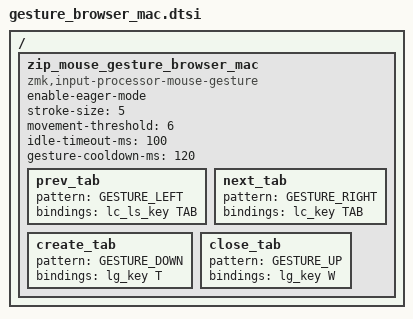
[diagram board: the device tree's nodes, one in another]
/ {
  zip_mouse_gesture_browser_mac: zip_mouse_gesture_browser_mac {
    compatible = "zmk,input-processor-mouse-gesture";
    #input-processor-cells = <0>;
    enable-eager-mode;
    stroke-size = <5>;
    movement-threshold = <6>;
    idle-timeout-ms = <100>;
    gesture-cooldown-ms = <120>;

    prev_tab   { pattern = <GESTURE_LEFT>;  bindings = <&lc_ls_key TAB>; };  // 前のタブ（Mac同じ）
    next_tab   { pattern = <GESTURE_RIGHT>; bindings = <&lc_key TAB>;    };  // 次のタブ（Mac同じ）
    create_tab { pattern = <GESTURE_DOWN>;  bindings = <&lg_key T>;      };  // 新規タブ Cmd+T（invert-y: 物理上 → GESTURE_DOWN）
    close_tab  { pattern = <GESTURE_UP>;    bindings = <&lg_key W>;      };  // タブ閉じる Cmd+W（invert-y: 物理下 → GESTURE_UP）
  };
};
